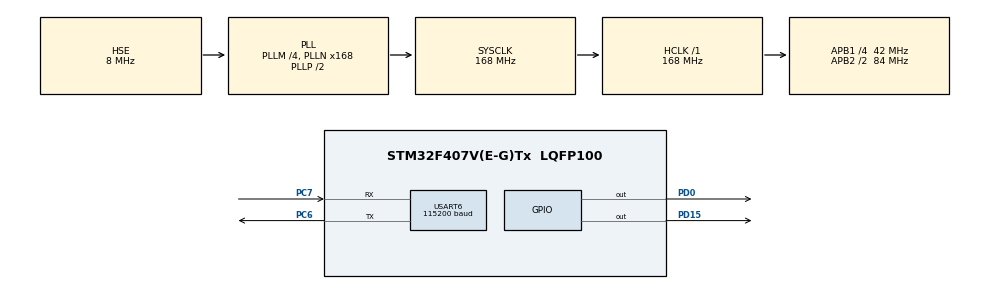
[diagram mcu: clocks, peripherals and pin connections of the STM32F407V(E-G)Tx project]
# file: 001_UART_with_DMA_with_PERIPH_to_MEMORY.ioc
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Dma.Request0=USART6_RX
Dma.USART6_RX.0.Direction=DMA_PERIPH_TO_MEMORY
Dma.USART6_RX.0.FIFOMode=DMA_FIFOMODE_DISABLE
Dma.USART6_RX.0.Instance=DMA2_Stream1
Dma.USART6_RX.0.MemDataAlignment=DMA_MDATAALIGN_BYTE
Dma.USART6_RX.0.MemInc=DMA_MINC_DISABLE
Dma.USART6_RX.0.Mode=DMA_CIRCULAR
Dma.USART6_RX.0.PeriphDataAlignment=DMA_PDATAALIGN_BYTE
Dma.USART6_RX.0.PeriphInc=DMA_PINC_DISABLE
Dma.USART6_RX.0.Priority=DMA_PRIORITY_LOW
Mcu.Family=STM32F4
Mcu.Name=STM32F407V(E-G)Tx
Mcu.Package=LQFP100
NVIC.DMA2_Stream1_IRQn=true\:0\:0\:false\:false\:true\:false\:true
NVIC.PriorityGroup=NVIC_PRIORITYGROUP_0
PC6.Mode=Asynchronous
PC6.Signal=USART6_TX
PC7.Mode=Asynchronous
PC7.Signal=USART6_RX
PD0.Signal=GPIO_Output
PD15.Signal=GPIO_Output
PH0-OSC_IN.Mode=HSE-External-Oscillator
PH0-OSC_IN.Signal=RCC_OSC_IN
PH1-OSC_OUT.Mode=HSE-External-Oscillator
PH1-OSC_OUT.Signal=RCC_OSC_OUT
ProjectManager.HeapSize=0x200
ProjectManager.StackSize=0x400
ProjectManager.TargetToolchain=STM32CubeIDE
RCC.48MHZClocksFreq_Value=48000000
RCC.AHBFreq_Value=168000000
RCC.APB1CLKDivider=RCC_HCLK_DIV4
RCC.APB1Freq_Value=42000000
RCC.APB1TimFreq_Value=84000000
RCC.APB2CLKDivider=RCC_HCLK_DIV2
RCC.APB2Freq_Value=84000000
RCC.APB2TimFreq_Value=168000000
RCC.CortexFreq_Value=168000000
RCC.EnbaleCSS=true
RCC.HCLKFreq_Value=168000000
RCC.HSE_VALUE=8000000
RCC.HSI_VALUE=16000000
RCC.LSE_VALUE=32768
RCC.PLLM=4
RCC.PLLN=168
RCC.PLLQ=7
RCC.PLLSourceVirtual=RCC_PLLSOURCE_HSE
RCC.SYSCLKFreq_VALUE=168000000
RCC.SYSCLKSource=RCC_SYSCLKSOURCE_PLLCLK
RCC.VCOOutputFreq_Value=336000000
USART6.BaudRate=115200
USART6.VirtualMode=VM_ASYNC
board=STM32F407G-DISC1

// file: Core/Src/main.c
/* USER CODE BEGIN Header */
/**
  ******************************************************************************
  * @file           : main.c
  * @brief          : Main program body
  ******************************************************************************
  * @attention
  *
  * Copyright (c) 2021 STMicroelectronics.
  * All rights reserved.
  *
  * This software is licensed under terms that can be found in the LICENSE file
  * in the root directory of this software component.
  * If no LICENSE file comes with this software, it is provided AS-IS.
  *
  ******************************************************************************
  */
/* USER CODE END Header */
#include "main.h"

UART_HandleTypeDef huart6;
DMA_HandleTypeDef hdma_usart6_rx;

void SystemClock_Config(void);
static void MX_GPIO_Init(void);
static void MX_DMA_Init(void);
static void MX_USART6_UART_Init(void);

int main(void)
{

  /* MCU Configuration--------------------------------------------------------*/

  /* Reset of all peripherals, Initializes the Flash interface and the Systick. */
  HAL_Init();

  /* Configure the system clock */
  SystemClock_Config();

  /* Initialize all configured peripherals */
  MX_GPIO_Init();
  MX_DMA_Init();
  MX_USART6_UART_Init();
  /* USER CODE BEGIN 2 */
  /*I had problems with usart2. I couldn't use dma mode with it. but somehow when I used usart6 it worked without problem.
   * after little research i find out that DMA1 doesnt have full access to Bus-Matrix.(for stm32f4 family)
   * so gotta use DMA2 for full Bus-Matrix access.
   */
  HAL_DMA_Start(&hdma_usart6_rx,  (uint32_t)&huart6.Instance->DR,  (uint32_t)&GPIOD->ODR, 1);
  huart6.Instance->CR3 |= USART_CR3_DMAR;

  /* USER CODE END 2 */

  /* Infinite loop */
  while (1)
  {

  }
}

void SystemClock_Config(void)
{
  RCC_OscInitTypeDef RCC_OscInitStruct = {0};
  RCC_ClkInitTypeDef RCC_ClkInitStruct = {0};

  /** Configure the main internal regulator output voltage
  */
  __HAL_RCC_PWR_CLK_ENABLE();
  __HAL_PWR_VOLTAGESCALING_CONFIG(PWR_REGULATOR_VOLTAGE_SCALE1);
  /** Initializes the RCC Oscillators according to the specified parameters
  * in the RCC_OscInitTypeDef structure.
  */
  RCC_OscInitStruct.OscillatorType = RCC_OSCILLATORTYPE_HSE;
  RCC_OscInitStruct.HSEState = RCC_HSE_ON;
  RCC_OscInitStruct.PLL.PLLState = RCC_PLL_ON;
  RCC_OscInitStruct.PLL.PLLSource = RCC_PLLSOURCE_HSE;
  RCC_OscInitStruct.PLL.PLLM = 4;
  RCC_OscInitStruct.PLL.PLLN = 168;
  RCC_OscInitStruct.PLL.PLLP = RCC_PLLP_DIV2;
  RCC_OscInitStruct.PLL.PLLQ = 7;
  if (HAL_RCC_OscConfig(&RCC_OscInitStruct) != HAL_OK)
  {
    Error_Handler();
  }
  /** Initializes the CPU, AHB and APB buses clocks
  */
  RCC_ClkInitStruct.ClockType = RCC_CLOCKTYPE_HCLK|RCC_CLOCKTYPE_SYSCLK
                              |RCC_CLOCKTYPE_PCLK1|RCC_CLOCKTYPE_PCLK2;
  RCC_ClkInitStruct.SYSCLKSource = RCC_SYSCLKSOURCE_PLLCLK;
  RCC_ClkInitStruct.AHBCLKDivider = RCC_SYSCLK_DIV1;
  RCC_ClkInitStruct.APB1CLKDivider = RCC_HCLK_DIV4;
  RCC_ClkInitStruct.APB2CLKDivider = RCC_HCLK_DIV2;

  if (HAL_RCC_ClockConfig(&RCC_ClkInitStruct, FLASH_LATENCY_5) != HAL_OK)
  {
    Error_Handler();
  }
  /** Enables the Clock Security System
  */
  HAL_RCC_EnableCSS();
}

static void MX_USART6_UART_Init(void)
{

  huart6.Instance = USART6;
  huart6.Init.BaudRate = 115200;
  huart6.Init.WordLength = UART_WORDLENGTH_8B;
  huart6.Init.StopBits = UART_STOPBITS_1;
  huart6.Init.Parity = UART_PARITY_NONE;
  huart6.Init.Mode = UART_MODE_TX_RX;
  huart6.Init.HwFlowCtl = UART_HWCONTROL_NONE;
  huart6.Init.OverSampling = UART_OVERSAMPLING_16;
  if (HAL_UART_Init(&huart6) != HAL_OK)
  {
    Error_Handler();
  }

}

static void MX_DMA_Init(void)
{

  /* DMA controller clock enable */
  __HAL_RCC_DMA2_CLK_ENABLE();

  /* DMA interrupt init */
  /* DMA2_Stream1_IRQn interrupt configuration */
  HAL_NVIC_SetPriority(DMA2_Stream1_IRQn, 0, 0);
  HAL_NVIC_EnableIRQ(DMA2_Stream1_IRQn);

}

static void MX_GPIO_Init(void)
{
  GPIO_InitTypeDef GPIO_InitStruct = {0};

  /* GPIO Ports Clock Enable */
  __HAL_RCC_GPIOH_CLK_ENABLE();
  __HAL_RCC_GPIOD_CLK_ENABLE();
  __HAL_RCC_GPIOC_CLK_ENABLE();

  /*Configure GPIO pin Output Level */
  HAL_GPIO_WritePin(GPIOD, GPIO_PIN_15|GPIO_PIN_0, GPIO_PIN_RESET);

  /*Configure GPIO pins : PD15 PD0 */
  GPIO_InitStruct.Pin = GPIO_PIN_15|GPIO_PIN_0;
  GPIO_InitStruct.Mode = GPIO_MODE_OUTPUT_PP;
  GPIO_InitStruct.Pull = GPIO_NOPULL;
  GPIO_InitStruct.Speed = GPIO_SPEED_FREQ_LOW;
  HAL_GPIO_Init(GPIOD, &GPIO_InitStruct);

}

void Error_Handler(void)
{
  __disable_irq();
  while (1)
  {
  }
}
